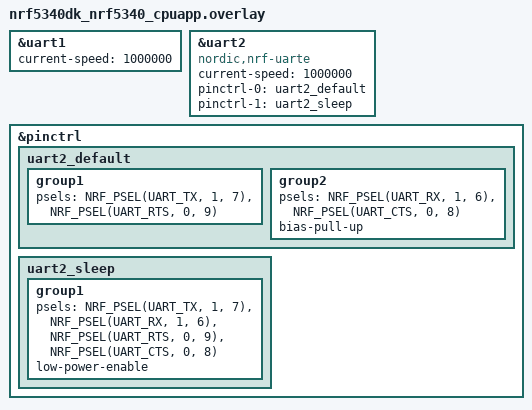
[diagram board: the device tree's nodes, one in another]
/*
 * Copyright (c) 2025 Nordic Semiconductor ASA
 *
 * SPDX-License-Identifier: Apache-2.0
 */

&uart1 {
	status = "okay";
	current-speed = <1000000>;
	/delete-property/ hw-flow-control;
};

&uart2 {
	compatible = "nordic,nrf-uarte";
	status = "okay";
	current-speed = <1000000>;
	pinctrl-0 = <&uart2_default>;
	pinctrl-1 = <&uart2_sleep>;
	pinctrl-names = "default", "sleep";
	/delete-property/ hw-flow-control;
};

&pinctrl {
	uart2_default: uart2_default {
		group1 {
			psels = <NRF_PSEL(UART_TX, 1, 7)>,
				<NRF_PSEL(UART_RTS, 0, 9)>;
		};

		group2 {
			psels = <NRF_PSEL(UART_RX, 1, 6)>,
				<NRF_PSEL(UART_CTS, 0, 8)>;
			bias-pull-up;
		};
	};

	uart2_sleep: uart2_sleep {
		group1 {
			psels = <NRF_PSEL(UART_TX, 1, 7)>,
				<NRF_PSEL(UART_RX, 1, 6)>,
				<NRF_PSEL(UART_RTS, 0, 9)>,
				<NRF_PSEL(UART_CTS, 0, 8)>;
			low-power-enable;
		};
	};
};
